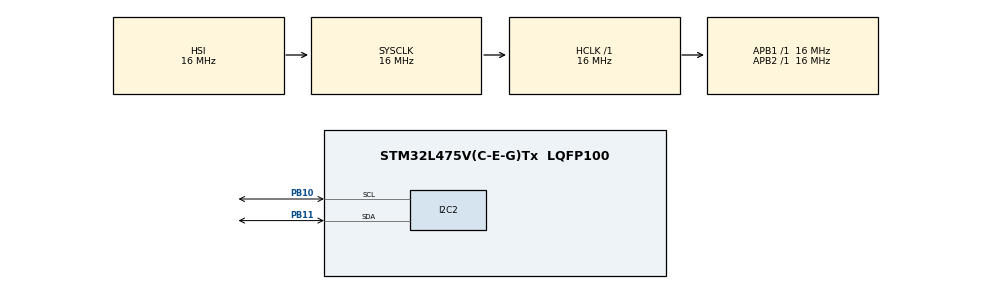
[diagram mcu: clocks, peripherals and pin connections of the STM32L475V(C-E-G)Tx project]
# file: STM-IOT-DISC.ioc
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I2C2.Timing=0x00503D58
Mcu.Family=STM32L4
Mcu.Name=STM32L475V(C-E-G)Tx
Mcu.Package=LQFP100
NVIC.PriorityGroup=NVIC_PRIORITYGROUP_4
PB10.Mode=I2C
PB10.Signal=I2C2_SCL
PB11.Mode=I2C
PB11.Signal=I2C2_SDA
ProjectManager.HeapSize=0x200
ProjectManager.StackSize=0x400
ProjectManager.TargetToolchain=STM32CubeIDE
RCC.ADCFreq_Value=192000000
RCC.AHBFreq_Value=16000000
RCC.APB1Freq_Value=16000000
RCC.APB1TimFreq_Value=16000000
RCC.APB2Freq_Value=16000000
RCC.APB2TimFreq_Value=16000000
RCC.CortexFreq_Value=16000000
RCC.HCLKFreq_Value=16000000
RCC.HSE_VALUE=8000000
RCC.HSI_VALUE=16000000
RCC.LSE_VALUE=32768
RCC.MSI_VALUE=4000000
RCC.PLLN=40
RCC.PLLSAI1N=24
RCC.PLLSourceVirtual=RCC_PLLSOURCE_HSI
RCC.SYSCLKFreq_VALUE=16000000
RCC.SYSCLKSource=RCC_SYSCLKSOURCE_HSI
RCC.USBFreq_Value=192000000
RCC.VCOOutputFreq_Value=640000000
board=B-L475E-IOT01A1

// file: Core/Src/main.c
/* USER CODE BEGIN Header */
/**
  ******************************************************************************
  * @file           : main.c
  * @brief          : Main program body
  ******************************************************************************
  * @attention
  *
  * Copyright (c) 2026 STMicroelectronics.
  * All rights reserved.
  *
  * This software is licensed under terms that can be found in the LICENSE file
  * in the root directory of this software component.
  * If no LICENSE file comes with this software, it is provided AS-IS.
  *
  ******************************************************************************
  */
/* USER CODE END Header */
#include "main.h"

/* USER CODE BEGIN Includes */
#include <stdio.h>
#include "HTS221.h"
/* USER CODE END Includes */

I2C_HandleTypeDef hi2c2;

void SystemClock_Config(void);
static void MX_GPIO_Init(void);
static void MX_I2C2_Init(void);
void Error_Handler(void);
float H0_RH;
float H1_RH;

float T0_degC;
float T1_degC;

int16_t H0_T0_OUT;
int16_t H1_T0_OUT;

int16_t T0_OUT;
int16_t T1_OUT;

uint8_t ctrl = 0x85;

/* USER CODE BEGIN PFP */
int __io_putchar(int ch)
{
    ITM_SendChar(ch);
    return ch;
}

int16_t raw_humidity;
int16_t raw_temperature;

float humidity;
float temperature;
/* USER CODE END PFP */

int main(void)
{

  /* MCU Configuration--------------------------------------------------------*/

  /* Reset of all peripherals, Initializes the Flash interface and the Systick. */
  HAL_Init();

  /* Configure the system clock */
  SystemClock_Config();

  /* Initialize all configured peripherals */
  MX_GPIO_Init();
  MX_I2C2_Init();
  /* USER CODE BEGIN 2 */
  HAL_I2C_Mem_Write(&hi2c2,
                    HTS221_ADDR,
                    CTRL_REG1,
                    I2C_MEMADD_SIZE_8BIT,
                    &ctrl,
                    1,
                    HAL_MAX_DELAY);
  HTS221_ReadCalibration();
  /* USER CODE END 2 */

  /* Infinite loop */
  while (1)
  {

    /* USER CODE BEGIN 3 */
	  HTS221_ReadRaw(&raw_humidity,
	                    &raw_temperature);

	     humidity =
	         HTS221_GetHumidity(raw_humidity);

	     temperature =
	         HTS221_GetTemperature(raw_temperature);

	     printf("Temperature = %.2f C\r\n", temperature);
	     printf("Humidity    = %.2f %%\r\n", humidity);

	     HAL_Delay(1000);

  }
  /* USER CODE END 3 */
}

void SystemClock_Config(void)
{
  RCC_OscInitTypeDef RCC_OscInitStruct = {0};
  RCC_ClkInitTypeDef RCC_ClkInitStruct = {0};

  /** Configure the main internal regulator output voltage
  */
  if (HAL_PWREx_ControlVoltageScaling(PWR_REGULATOR_VOLTAGE_SCALE1) != HAL_OK)
  {
    Error_Handler();
  }

  /** Initializes the RCC Oscillators according to the specified parameters
  * in the RCC_OscInitTypeDef structure.
  */
  RCC_OscInitStruct.OscillatorType = RCC_OSCILLATORTYPE_HSI;
  RCC_OscInitStruct.HSIState = RCC_HSI_ON;
  RCC_OscInitStruct.HSICalibrationValue = RCC_HSICALIBRATION_DEFAULT;
  RCC_OscInitStruct.PLL.PLLState = RCC_PLL_NONE;
  if (HAL_RCC_OscConfig(&RCC_OscInitStruct) != HAL_OK)
  {
    Error_Handler();
  }

  /** Initializes the CPU, AHB and APB buses clocks
  */
  RCC_ClkInitStruct.ClockType = RCC_CLOCKTYPE_HCLK|RCC_CLOCKTYPE_SYSCLK
                              |RCC_CLOCKTYPE_PCLK1|RCC_CLOCKTYPE_PCLK2;
  RCC_ClkInitStruct.SYSCLKSource = RCC_SYSCLKSOURCE_HSI;
  RCC_ClkInitStruct.AHBCLKDivider = RCC_SYSCLK_DIV1;
  RCC_ClkInitStruct.APB1CLKDivider = RCC_HCLK_DIV1;
  RCC_ClkInitStruct.APB2CLKDivider = RCC_HCLK_DIV1;

  if (HAL_RCC_ClockConfig(&RCC_ClkInitStruct, FLASH_LATENCY_0) != HAL_OK)
  {
    Error_Handler();
  }
}

static void MX_I2C2_Init(void)
{

  hi2c2.Instance = I2C2;
  hi2c2.Init.Timing = 0x00503D58;
  hi2c2.Init.OwnAddress1 = 0;
  hi2c2.Init.AddressingMode = I2C_ADDRESSINGMODE_7BIT;
  hi2c2.Init.DualAddressMode = I2C_DUALADDRESS_DISABLE;
  hi2c2.Init.OwnAddress2 = 0;
  hi2c2.Init.OwnAddress2Masks = I2C_OA2_NOMASK;
  hi2c2.Init.GeneralCallMode = I2C_GENERALCALL_DISABLE;
  hi2c2.Init.NoStretchMode = I2C_NOSTRETCH_DISABLE;
  if (HAL_I2C_Init(&hi2c2) != HAL_OK)
  {
    Error_Handler();
  }

  /** Configure Analogue filter
  */
  if (HAL_I2CEx_ConfigAnalogFilter(&hi2c2, I2C_ANALOGFILTER_ENABLE) != HAL_OK)
  {
    Error_Handler();
  }

  /** Configure Digital filter
  */
  if (HAL_I2CEx_ConfigDigitalFilter(&hi2c2, 0) != HAL_OK)
  {
    Error_Handler();
  }

}

static void MX_GPIO_Init(void)
{

  /* GPIO Ports Clock Enable */
  __HAL_RCC_GPIOB_CLK_ENABLE();

}

void Error_Handler(void)
{
  __disable_irq();
  while (1)
  {
  }
}
